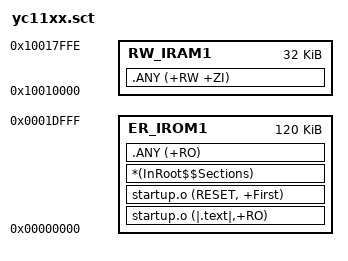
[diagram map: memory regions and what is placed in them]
; *************************************************************
; *** Scatter-Loading Description File generated by uVision ***
; *************************************************************

LR_IROM1 0x00000000 0x0001E000  {    ; load region size_region
  ER_IROM1 0x00000000 0x0001E000  {  ; load address = execution address
   startup.o (|.text|,+RO)
   startup.o (RESET, +First)
	*(InRoot$$Sections)
	.ANY (+RO)
  }
	; if change this, must change startup.s __initial_sp
	 RW_IRAM1 0x10010000 0x7fff  {  ; RW data
	.ANY (+RW +ZI)
	}
}

